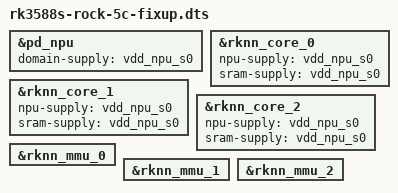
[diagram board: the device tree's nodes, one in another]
// SPDX-License-Identifier: (GPL-2.0+ OR MIT)

#include "rk3588s-rock-5c.dts"

&pd_npu {
	domain-supply = <&vdd_npu_s0>;
};

&rknn_core_0 {
	npu-supply = <&vdd_npu_s0>;
	sram-supply = <&vdd_npu_s0>;
	status = "okay";
};

&rknn_core_1 {
	npu-supply = <&vdd_npu_s0>;
	sram-supply = <&vdd_npu_s0>;
	status = "okay";
};

&rknn_core_2 {
	npu-supply = <&vdd_npu_s0>;
	sram-supply = <&vdd_npu_s0>;
	status = "okay";
};

&rknn_mmu_0 {
	status = "okay";
};

&rknn_mmu_1 {
	status = "okay";
};

&rknn_mmu_2 {
	status = "okay";
};
